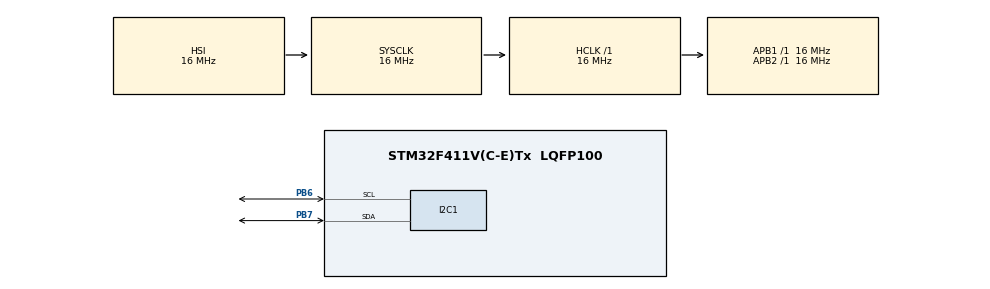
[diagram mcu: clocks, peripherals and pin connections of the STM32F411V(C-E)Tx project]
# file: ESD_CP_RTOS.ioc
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FREERTOS.Tasks01=defaultTask,-1,128,StartDefaultTask,Default,NULL,Dynamic,NULL,NULL;Task_IRSensor,1,128,Task_IR_Entry,Default,NULL,Dynamic,NULL,NULL;Regular_op,0,128,Regular_entry,Default,NULL,Dynamic,NULL,NULL
FREERTOS.configUSE_NEWLIB_REENTRANT=1
I2C1.I2C_Mode=I2C_Fast
Mcu.Family=STM32F4
Mcu.Name=STM32F411V(C-E)Tx
Mcu.Package=LQFP100
NVIC.PriorityGroup=NVIC_PRIORITYGROUP_4
NVIC.TIM1_UP_TIM10_IRQn=true\:15\:0\:false\:false\:true\:false\:false\:true
NVIC.TimeBase=TIM1_UP_TIM10_IRQn
NVIC.TimeBaseIP=TIM1
PA13.Mode=Serial_Wire
PA13.Signal=SYS_JTMS-SWDIO
PA14.Mode=Serial_Wire
PA14.Signal=SYS_JTCK-SWCLK
PB6.Mode=I2C
PB6.Signal=I2C1_SCL
PB7.Mode=I2C
PB7.Signal=I2C1_SDA
PH0\ -\ OSC_IN.Mode=HSE-External-Oscillator
PH0\ -\ OSC_IN.Signal=RCC_OSC_IN
PH1\ -\ OSC_OUT.Mode=HSE-External-Oscillator
PH1\ -\ OSC_OUT.Signal=RCC_OSC_OUT
ProjectManager.HeapSize=0x200
ProjectManager.StackSize=0x400
ProjectManager.TargetToolchain=STM32CubeIDE
RCC.AHBFreq_Value=16000000
RCC.APB1Freq_Value=16000000
RCC.APB2Freq_Value=16000000
RCC.CortexFreq_Value=16000000
RCC.HSE_VALUE=8000000
RCC.HSI_VALUE=16000000
RCC.LSE_VALUE=32768
RCC.SYSCLKFreq_VALUE=16000000
RCC.VCOOutputFreq_Value=192000000
VP_FREERTOS_VS_CMSIS_V1.Mode=CMSIS_V1
VP_SYS_VS_tim1.Mode=TIM1
board=custom

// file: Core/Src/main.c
/* USER CODE BEGIN Header */
/**
 ******************************************************************************
 * @file           : main.c
 * @brief          : Main program body
 ******************************************************************************
 * @attention
 *
 * <h2><center>&copy; Copyright (c) 2023 STMicroelectronics.
 * All rights reserved.</center></h2>
 *
 * This software component is licensed by ST under BSD 3-Clause license,
 * the "License"; You may not use this file except in compliance with the
 * License. You may obtain a copy of the License at:
 *                        opensource.org/licenses/BSD-3-Clause
 *
 ******************************************************************************
 */
/* USER CODE END Header */
#include "main.h"
#include "cmsis_os.h"

/* USER CODE BEGIN Includes */
#include "fonts.h"
#include "ssd1306.h"
#include "rtc.h"
#include "adc.h"
#include "ir_sensor.h"
#include "oled_ops.h"
#include "stdbool.h"
#include "timer.h"
/* USER CODE END Includes */

I2C_HandleTypeDef hi2c1;

osThreadId defaultTaskHandle;
osThreadId Sense_IRHandle;
osThreadId display_oledHandle;

void SystemClock_Config(void);
static void MX_GPIO_Init(void);
static void MX_I2C1_Init(void);
void StartDefaultTask(void const *argument);
void Sense_IR_Entry(void const *argument);
void display_oled_enter(void const *argument);

/* USER CODE BEGIN 0 */
#define PA5_SET 5
#define PA5_CLEAR 21
static bool clear_oled_left = true;
static bool clear_oled_right = true;
static bool clear_oled_both = true;
static bool clear_oled_default = true;
static unsigned char Left_Alert_NEW [] = {
0xFF, 0xFF, 0xFF, 0xFF, 0xFF, 0xFF, 0xFF, 0xFF, 0xFF, 0xFF, 0xFF, 0xFF, 0xFF, 0xFF, 0xFF, 0xFF,
0xFF, 0xFF, 0xFF, 0xFF, 0xFF, 0xFF, 0xFF, 0xFF, 0xFF, 0xFF, 0xFF, 0xFF, 0xFF, 0xFF, 0xFF, 0xFF,
0xFF, 0xFF, 0xFF, 0xFF, 0xFF, 0xFF, 0xFF, 0xFF, 0xFF, 0xFF, 0xFF, 0xFF, 0xFF, 0xFF, 0xFF, 0xFF,
0xFF, 0xFF, 0xFF, 0xFF, 0xFF, 0xFF, 0xFF, 0xF0, 0x03, 0xFF, 0xFF, 0xFF, 0xFF, 0xFF, 0xFF, 0xFF,
0xFF, 0xFF, 0xFF, 0xFF, 0xFF, 0xFF, 0xFF, 0xE0, 0x01, 0xFF, 0xFF, 0xFF, 0xFF, 0xFF, 0xFF, 0xFF,
0xFF, 0xFF, 0xFF, 0xFF, 0xFF, 0xFF, 0xFF, 0xE0, 0x01, 0xFF, 0xFF, 0xFF, 0xFF, 0xFF, 0xFF, 0xFF,
0xFF, 0xFF, 0xFF, 0xFF, 0xFF, 0xFF, 0xFF, 0xC0, 0x00, 0x7F, 0xFF, 0xFF, 0xFF, 0xFF, 0xFF, 0xFF,
0xFF, 0xFF, 0xFF, 0xFF, 0xFF, 0xFF, 0xFE, 0x00, 0x00, 0x1F, 0xFF, 0xFF, 0xFF, 0xFF, 0xFF, 0xFF,
0xFF, 0xFF, 0xFF, 0xFF, 0xFF, 0xFF, 0xFC, 0x00, 0x00, 0x0F, 0xFF, 0xFF, 0xFF, 0xFF, 0xFF, 0xFF,
0xFF, 0xFF, 0xFF, 0xFF, 0xFF, 0xFF, 0xFC, 0x00, 0x00, 0x0F, 0xFF, 0xFF, 0xFF, 0xFF, 0xFF, 0xFF,
0xFF, 0xFF, 0xFF, 0xFF, 0xFF, 0xFF, 0xFC, 0x00, 0x00, 0x0F, 0xFF, 0xFF, 0xFF, 0xFF, 0xFF, 0xFF,
0xFF, 0xFF, 0xFF, 0xFF, 0xFF, 0xFF, 0xF8, 0x00, 0x00, 0x0F, 0xFF, 0xFF, 0xFF, 0xFF, 0xFF, 0xFF,
0xFF, 0xFF, 0xFF, 0xFF, 0xFF, 0xFF, 0xF8, 0x00, 0x00, 0x0F, 0xFF, 0xFF, 0xFF, 0xFF, 0xFF, 0xFF,
0xFF, 0xFF, 0xFF, 0xFF, 0xFF, 0xFF, 0xF8, 0x00, 0x00, 0x0F, 0xFF, 0xFF, 0xFF, 0xFF, 0xFF, 0xFF,
0xFF, 0xFF, 0xFF, 0xFF, 0xFF, 0xFF, 0xF8, 0x00, 0x00, 0x0F, 0xFF, 0xFF, 0xFF, 0xFF, 0xFF, 0xFF,
0xFF, 0xFF, 0xFF, 0xFF, 0xFF, 0xFF, 0xF8, 0x00, 0x00, 0x0F, 0xFF, 0xFF, 0xFF, 0xFF, 0xFF, 0xFF,
0xFF, 0xFF, 0xFF, 0xFF, 0xFF, 0xFF, 0xFC, 0x03, 0xF8, 0x0F, 0xFF, 0xFF, 0xFF, 0xFF, 0xFF, 0xFF,
0xFF, 0xFF, 0xFF, 0xFF, 0xFF, 0xFF, 0xFC, 0x1F, 0xFE, 0x0F, 0xFF, 0xFF, 0xFF, 0xFF, 0xFF, 0xFF,
0xFF, 0xFF, 0xFF, 0xFF, 0xFF, 0xFF, 0xFC, 0x3F, 0xFF, 0x8F, 0xFF, 0xFF, 0xFF, 0xFF, 0xFF, 0xFF,
0xFF, 0xFF, 0xFF, 0xFF, 0xFF, 0xFF, 0xFC, 0x7F, 0xFF, 0x8F, 0xFF, 0xFF, 0xFF, 0xFF, 0xFF, 0xFF,
0xFF, 0xFF, 0xFF, 0xFF, 0xFF, 0xFF, 0xFC, 0x7F, 0xFF, 0xCF, 0xFF, 0xFF, 0xFF, 0xFF, 0xFF, 0xFF,
0xFF, 0xFF, 0xFF, 0xFF, 0xFF, 0xFF, 0xFC, 0x7F, 0xFF, 0xCF, 0xFF, 0xFF, 0xFF, 0xFF, 0xFF, 0xFF,
0xFF, 0xFF, 0xFF, 0xFF, 0xFF, 0xFF, 0xFC, 0x7F, 0xFF, 0x8F, 0xFF, 0xFF, 0xFF, 0xFF, 0xFF, 0xFF,
0xFF, 0xFF, 0xFF, 0xFF, 0xFF, 0xFF, 0xFC, 0x7F, 0xFF, 0x8F, 0xFF, 0xFF, 0xFF, 0xFF, 0xFF, 0xFF,
0xFF, 0xFF, 0xFF, 0xFF, 0xFF, 0xFF, 0xF0, 0x7F, 0xFF, 0x83, 0xFF, 0xFF, 0xFF, 0xFF, 0xFF, 0xFF,
0xFF, 0xFF, 0xFF, 0xFF, 0xFF, 0xFF, 0xF4, 0x3F, 0xFF, 0xAF, 0xFF, 0xFF, 0xFF, 0xFF, 0xFF, 0xFF,
0xFF, 0xFF, 0xFF, 0xFF, 0xFF, 0xFF, 0xFC, 0xBF, 0xFF, 0x2F, 0xFF, 0xFF, 0xFF, 0xFF, 0xFF, 0xFF,
0xFF, 0xFF, 0xFF, 0xFF, 0xFF, 0xFF, 0xFC, 0x80, 0x00, 0x2F, 0xFF, 0xFF, 0xFF, 0xFF, 0xFF, 0xFF,
0xFF, 0xFF, 0xFF, 0xFF, 0xFF, 0xFF, 0xFC, 0x80, 0x00, 0x6F, 0xFF, 0xFF, 0xFF, 0xFF, 0xFF, 0xFF,
0xFF, 0xFF, 0xFF, 0xFF, 0xFF, 0xFF, 0xFC, 0x80, 0x00, 0x6F, 0xFF, 0xFF, 0xFF, 0xFF, 0xFF, 0xFF,
0xFF, 0xFF, 0xFF, 0xFF, 0xFF, 0xFF, 0xFC, 0x80, 0x00, 0x6F, 0xFF, 0xFF, 0xFF, 0xFF, 0xFF, 0xFF,
0xFF, 0xFF, 0xFF, 0xFF, 0xFF, 0xFF, 0xFC, 0xC0, 0x00, 0x6F, 0xFF, 0xFF, 0xFF, 0xFF, 0xFF, 0xFF,
0xFF, 0xFF, 0xFF, 0xFF, 0xFF, 0xFF, 0xFC, 0xC0, 0x00, 0x6F, 0xFF, 0xFF, 0xFF, 0xFF, 0xFF, 0xFF,
0xFF, 0xFF, 0xFF, 0xFF, 0xFF, 0xFF, 0xFC, 0xC0, 0x00, 0x6F, 0xFF, 0xFF, 0xFF, 0xFF, 0xFF, 0xFF,
0xFF, 0xFF, 0xFF, 0xFF, 0xFF, 0xFF, 0xFC, 0xC0, 0x00, 0x6F, 0xFF, 0xFF, 0xFF, 0xFF, 0xFF, 0xFF,
0xFF, 0xFF, 0xFF, 0xFF, 0xFF, 0xFF, 0xFC, 0xC0, 0x00, 0x6F, 0xFF, 0xFF, 0xFF, 0xFF, 0xFF, 0xFF,
0xFF, 0xFF, 0xFF, 0xFF, 0xFF, 0xFF, 0xFC, 0xC0, 0x00, 0x6F, 0xFF, 0xFF, 0xFF, 0xFF, 0xFF, 0xFF,
0xFF, 0xFF, 0xFF, 0xFF, 0xFF, 0xFF, 0xFC, 0xC0, 0x00, 0x6F, 0xFF, 0xFF, 0xFF, 0xFF, 0xFF, 0xFF,
0xFF, 0xFF, 0xFF, 0xFF, 0xFF, 0xFF, 0xFC, 0xC0, 0x00, 0x6F, 0xFF, 0xFF, 0xFF, 0xFF, 0xFF, 0xFF,
0xFF, 0xFF, 0xFF, 0xFF, 0xFF, 0xFF, 0xFC, 0xC0, 0x00, 0x6F, 0xFF, 0xFF, 0xFF, 0xFF, 0xFF, 0xFF,
0xFF, 0xFF, 0xFF, 0xFF, 0xFF, 0xFF, 0xFC, 0xC0, 0x00, 0x4F, 0xFF, 0xFF, 0xFF, 0xFF, 0xFF, 0xFF,
0xFF, 0xFF, 0xFF, 0xFF, 0xFF, 0xFF, 0xFC, 0x40, 0x00, 0x4F, 0xFF, 0xFF, 0xFF, 0xFF, 0xFF, 0xFF,
0xFF, 0xFF, 0xFF, 0xFF, 0xFF, 0xFF, 0xF8, 0x00, 0x00, 0x0F, 0xFF, 0xFF, 0xFF, 0xFF, 0xFF, 0xFF,
0xFF, 0xFF, 0xFF, 0xFF, 0xFF, 0xFF, 0xF8, 0x00, 0x00, 0x0F, 0xFF, 0xFF, 0xFF, 0xFF, 0xFF, 0xFF,
0xFF, 0xFF, 0xFF, 0xFF, 0xFF, 0xFF, 0xF8, 0x1F, 0xFF, 0x0F, 0xFF, 0xFF, 0xFF, 0xFF, 0xFF, 0xFF,
0xFF, 0xFF, 0xFF, 0xFF, 0xFF, 0xDF, 0xF8, 0x3F, 0xFF, 0x0F, 0xFF, 0xFF, 0xFF, 0xFF, 0xFF, 0xFF,
0xFF, 0xFF, 0xFF, 0xFF, 0xFF, 0xDF, 0xFC, 0x1F, 0xFF, 0x0F, 0xFF, 0xFF, 0xFF, 0xFF, 0xFF, 0xFF,
0xFF, 0xFF, 0xFF, 0xFF, 0xFF, 0xCD, 0xFC, 0x1F, 0xFE, 0x0F, 0xFF, 0xFF, 0xFF, 0xFF, 0xFF, 0xFF,
0xFF, 0xFF, 0xFF, 0xFF, 0xFF, 0xED, 0xFC, 0x1F, 0xFE, 0x0F, 0xFF, 0xFF, 0xFF, 0xFF, 0xFF, 0xFF,
0xFF, 0xFF, 0xFF, 0xFF, 0xFF, 0xEC, 0x9C, 0x1F, 0xFE, 0x0F, 0xFF, 0xFF, 0xFF, 0xFF, 0xFF, 0xFF,
0xFF, 0xFF, 0xFF, 0xFF, 0xFF, 0xE6, 0xDC, 0x0F, 0xFC, 0x0F, 0xFF, 0xFF, 0xFF, 0xFF, 0xFF, 0xFF,
0xFF, 0xFF, 0xFF, 0xFF, 0xFF, 0xF6, 0x5C, 0x07, 0xF8, 0x1F, 0xFF, 0xFF, 0xFF, 0xFF, 0xFF, 0xFF,
0xFF, 0xFF, 0xFF, 0xFF, 0xFF, 0xF3, 0x4E, 0x00, 0x00, 0x1F, 0xFF, 0xFF, 0xFF, 0xFF, 0xFF, 0xFF,
0xFF, 0xFF, 0xFF, 0xFF, 0xFF, 0xFB, 0x2E, 0x00, 0x00, 0x1F, 0xFF, 0xFF, 0xFF, 0xFF, 0xFF, 0xFF,
0xFF, 0xFF, 0xFF, 0xFF, 0xFF, 0xF9, 0xA6, 0x00, 0x00, 0x3F, 0xFF, 0xFF, 0xFF, 0xFF, 0xFF, 0xFF,
0xFF, 0xFF, 0xFF, 0xFF, 0xFF, 0xFC, 0x93, 0xC0, 0x00, 0xFF, 0xFF, 0xFF, 0xFF, 0xFF, 0xFF, 0xFF,
0xFF, 0xFF, 0xFF, 0xFF, 0xFF, 0xFE, 0xC8, 0x7F, 0xFF, 0xFF, 0xFF, 0xFF, 0xFF, 0xFF, 0xFF, 0xFF,
0xFF, 0xFF, 0xFF, 0xFF, 0xFF, 0xFF, 0x66, 0x1F, 0xFF, 0xFF, 0xFF, 0xFF, 0xFF, 0xFF, 0xFF, 0xFF,
0xFF, 0xFF, 0xFF, 0xFF, 0xFF, 0xFF, 0x30, 0x07, 0xFF, 0xFF, 0xFF, 0xFF, 0xFF, 0xFF, 0xFF, 0xFF,
0xFF, 0xFF, 0xFF, 0xFF, 0xFF, 0xFF, 0x9E, 0x1F, 0xFF, 0xFF, 0xFF, 0xFF, 0xFF, 0xFF, 0xFF, 0xFF,
0xFF, 0xFF, 0xFF, 0xFF, 0xFF, 0xFF, 0xE3, 0xF8, 0xFF, 0xFF, 0xFF, 0xFF, 0xFF, 0xFF, 0xFF, 0xFF,
0xFF, 0xFF, 0xFF, 0xFF, 0xFF, 0xFF, 0xF0, 0x03, 0xFF, 0xFF, 0xFF, 0xFF, 0xFF, 0xFF, 0xFF, 0xFF,
0xFF, 0xFF, 0xFF, 0xFF, 0xFF, 0xFF, 0xFF, 0xFF, 0xFF, 0xFF, 0xFF, 0xFF, 0xFF, 0xFF, 0xFF, 0xFF,
0xFF, 0xFF, 0xFF, 0xFF, 0xFF, 0xFF, 0xFF, 0xFF, 0xFF, 0xFF, 0xFF, 0xFF, 0xFF, 0xFF, 0xFF, 0xFF
};

static unsigned char Both_Side_Alert_NEW [] = {
0xFF, 0xFF, 0xFF, 0xFF, 0xFF, 0xFF, 0xFF, 0xFF, 0xFF, 0xFF, 0xFF, 0xFF, 0xFF, 0xFF, 0xFF, 0xFF,
0xFF, 0xFF, 0xFF, 0xFF, 0xFF, 0xFF, 0xFF, 0xFF, 0xFF, 0xFF, 0xFF, 0xFF, 0xFF, 0xFF, 0xFF, 0xFF,
0xFF, 0xFF, 0xFF, 0xFF, 0xFF, 0xFF, 0xFF, 0xFF, 0xFF, 0xFF, 0xFF, 0xFF, 0xFF, 0xFF, 0xFF, 0xFF,
0xFF, 0xFF, 0xFF, 0xFF, 0xFF, 0xFF, 0xFF, 0xFF, 0xFF, 0xFF, 0xFF, 0xFF, 0xFF, 0xFF, 0xFF, 0xFF,
0xFF, 0xFF, 0xFF, 0xFF, 0xFF, 0xFF, 0xFF, 0xFF, 0xFF, 0xFF, 0xFF, 0xFF, 0xFF, 0xFF, 0xFF, 0xFF,
0xFF, 0xFF, 0xFF, 0xFF, 0xFF, 0xFF, 0xFF, 0xFF, 0xFF, 0xFF, 0xFF, 0xFF, 0xFF, 0xFF, 0xFF, 0xFF,
0xFF, 0xFF, 0xFF, 0xFF, 0xFF, 0xFF, 0xFF, 0xFF, 0xFF, 0xFF, 0xFF, 0xFF, 0xFF, 0xFF, 0xFF, 0xFF,
0xFF, 0xFF, 0xFF, 0xFF, 0xFF, 0xFF, 0xFF, 0xC0, 0x7F, 0xFF, 0xFF, 0xFF, 0xFF, 0xFF, 0xFF, 0xFF,
0xFF, 0xFF, 0xFF, 0xFF, 0xFF, 0xFF, 0xFF, 0x00, 0x1F, 0xFF, 0xFF, 0xFF, 0xFF, 0xFF, 0xFF, 0xFF,
0xFF, 0xFF, 0xFF, 0xFF, 0xFF, 0xFF, 0xFF, 0x00, 0x1F, 0xFF, 0xFF, 0xFF, 0xFF, 0xFF, 0xFF, 0xFF,
0xFF, 0xFF, 0xFF, 0xFF, 0xFF, 0xFF, 0xFE, 0x00, 0x0F, 0xFF, 0xFF, 0xFF, 0xFF, 0xFF, 0xFF, 0xFF,
0xFF, 0xFF, 0xFF, 0xFF, 0xFF, 0xFF, 0xF0, 0x00, 0x01, 0xFF, 0xFF, 0xFF, 0xFF, 0xFF, 0xFF, 0xFF,
0xFF, 0xFF, 0xFF, 0xFF, 0xFF, 0xFF, 0xF0, 0x00, 0x01, 0xFF, 0xFF, 0xFF, 0xFF, 0xFF, 0xFF, 0xFF,
0xFF, 0xFF, 0xFF, 0xFF, 0xFF, 0xFF, 0xE0, 0x00, 0x00, 0xFF, 0xFF, 0xFF, 0xFF, 0xFF, 0xFF, 0xFF,
0xFF, 0xFF, 0xFF, 0xFF, 0xFF, 0xFF, 0xE0, 0x00, 0x00, 0xFF, 0xFF, 0xFF, 0xFF, 0xFF, 0xFF, 0xFF,
0xFF, 0xFF, 0xFF, 0xFF, 0xFF, 0xFF, 0xE0, 0x00, 0x00, 0xFF, 0xFF, 0xFF, 0xFF, 0xFF, 0xFF, 0xFF,
0xFF, 0xFF, 0xFF, 0xFF, 0xFF, 0xFF, 0xE0, 0x00, 0x00, 0xFF, 0xFF, 0xFF, 0xFF, 0xFF, 0xFF, 0xFF,
0xFF, 0xFF, 0xFF, 0xFF, 0xFF, 0xFF, 0xE0, 0x00, 0x00, 0xFF, 0xFF, 0xFF, 0xFF, 0xFF, 0xFF, 0xFF,
0xFF, 0xFF, 0xFF, 0xFF, 0xFF, 0xFF, 0xE0, 0x00, 0x00, 0xFF, 0xFF, 0xFF, 0xFF, 0xFF, 0xFF, 0xFF,
0xFF, 0xFF, 0xFF, 0xFF, 0xFF, 0xFF, 0xE0, 0x00, 0x00, 0xFF, 0xFF, 0xFF, 0xFF, 0xFF, 0xFF, 0xFF,
0xFF, 0xFF, 0xFF, 0xFF, 0xFF, 0xFF, 0xE0, 0x7F, 0xC0, 0xFF, 0xFF, 0xFF, 0xFF, 0xFF, 0xFF, 0xFF,
0xFF, 0xFF, 0xFF, 0xFF, 0xFF, 0xFF, 0xE1, 0xFF, 0xF0, 0xFF, 0xFF, 0xFF, 0xFF, 0xFF, 0xFF, 0xFF,
0xFF, 0xFF, 0xFF, 0xFF, 0xFF, 0xFF, 0xE3, 0xFF, 0xF8, 0xFF, 0xFF, 0xFF, 0xFF, 0xFF, 0xFF, 0xFF,
0xFF, 0xFF, 0xFF, 0xFF, 0xFF, 0xFF, 0xE3, 0xFF, 0xFC, 0xFF, 0xFF, 0xFF, 0xFF, 0xFF, 0xFF, 0xFF,
0xFF, 0xFF, 0xFF, 0xFF, 0xFF, 0xFF, 0xE3, 0xFF, 0xFC, 0xFF, 0xFF, 0xFF, 0xFF, 0xFF, 0xFF, 0xFF,
0xFF, 0xFF, 0xFF, 0xFF, 0xFF, 0xFF, 0xE3, 0xFF, 0xF8, 0xFF, 0xFF, 0xFF, 0xFF, 0xFF, 0xFF, 0xFF,
0xFF, 0xFF, 0xFF, 0xFF, 0xFF, 0xFF, 0xE3, 0xFF, 0xF8, 0xFF, 0xFF, 0xFF, 0xFF, 0xFF, 0xFF, 0xFF,
0xFF, 0xFF, 0xFF, 0xFF, 0xFF, 0xFF, 0xC3, 0xFF, 0xF8, 0x7F, 0xFF, 0xFF, 0xFF, 0xFF, 0xFF, 0xFF,
0xFF, 0xFF, 0xFF, 0xFF, 0xFF, 0xFF, 0xE1, 0xFF, 0xF8, 0xFF, 0xFF, 0xFF, 0xFF, 0xFF, 0xFF, 0xFF,
0xFF, 0xFF, 0xFF, 0xFF, 0xFF, 0xFF, 0xE4, 0xFF, 0xF0, 0xFF, 0xFF, 0xFF, 0xFF, 0xFF, 0xFF, 0xFF,
0xFF, 0xFF, 0xFF, 0xFF, 0xFF, 0xFF, 0xE4, 0x00, 0x04, 0xFF, 0xFF, 0xFF, 0xFF, 0xFF, 0xFF, 0xFF,
0xFF, 0xFF, 0xFF, 0xFF, 0xFF, 0xFF, 0xE4, 0x00, 0x04, 0xFF, 0xFF, 0xFF, 0xFF, 0xFF, 0xFF, 0xFF,
0xFF, 0xFF, 0xFF, 0xFF, 0xFF, 0xFF, 0xE4, 0x00, 0x04, 0xFF, 0xFF, 0xFF, 0xFF, 0xFF, 0xFF, 0xFF,
0xFF, 0xFF, 0xFF, 0xFF, 0xFF, 0xFF, 0xE6, 0x00, 0x04, 0xFF, 0xFF, 0xFF, 0xFF, 0xFF, 0xFF, 0xFF,
0xFF, 0xFF, 0xFF, 0xFF, 0xFF, 0xFF, 0xE6, 0x00, 0x04, 0xFF, 0xFF, 0xFF, 0xFF, 0xFF, 0xFF, 0xFF,
0xFF, 0xFF, 0xFF, 0xFF, 0xFF, 0xFF, 0xE6, 0x00, 0x04, 0xFF, 0xFF, 0xFF, 0xFF, 0xFF, 0xFF, 0xFF,
0xFF, 0xFF, 0xFF, 0xFF, 0xFF, 0xFF, 0xE6, 0x00, 0x04, 0xFF, 0xFF, 0xFF, 0xFF, 0xFF, 0xFF, 0xFF,
0xFF, 0xFF, 0xFF, 0xFF, 0xFF, 0xFF, 0xE6, 0x00, 0x04, 0xFF, 0xFF, 0xFF, 0xFF, 0xFF, 0xFF, 0xFF,
0xFF, 0xFF, 0xFF, 0xFF, 0xFF, 0xFF, 0xE6, 0x00, 0x04, 0xFF, 0xFF, 0xFF, 0xFF, 0xFF, 0xFF, 0xFF,
0xFF, 0xFF, 0xFF, 0xFF, 0xFF, 0xFF, 0xE6, 0x00, 0x04, 0xFF, 0xFF, 0xFF, 0xFF, 0xFF, 0xFF, 0xFF,
0xFF, 0xFF, 0xFF, 0xFF, 0xFF, 0xFF, 0xE6, 0x00, 0x04, 0xFF, 0xFF, 0xFF, 0xFF, 0xFF, 0xFF, 0xFF,
0xFF, 0xFF, 0xFF, 0xFF, 0xFF, 0xFF, 0xE6, 0x00, 0x04, 0xFF, 0xFF, 0xFF, 0xFF, 0xFF, 0xFF, 0xFF,
0xFF, 0xFF, 0xFF, 0xFF, 0xFF, 0xFF, 0xE6, 0x00, 0x04, 0xFF, 0xFF, 0xFF, 0xFF, 0xFF, 0xFF, 0xFF,
0xFF, 0xFF, 0xFF, 0xFF, 0xFF, 0xFF, 0xE2, 0x00, 0x04, 0xFF, 0xFF, 0xFF, 0xFF, 0xFF, 0xFF, 0xFF,
0xFF, 0xFF, 0xFF, 0xFF, 0xFF, 0xFF, 0xE0, 0x00, 0x00, 0xFF, 0xFF, 0xFF, 0xFF, 0xFF, 0xFF, 0xFF,
0xFF, 0xFF, 0xFF, 0xFF, 0xFF, 0xFF, 0xE0, 0xFF, 0xE0, 0xFF, 0xFF, 0xFF, 0xFF, 0xFF, 0xFF, 0xFF,
0xFF, 0xFF, 0xFF, 0xFF, 0xFF, 0xFF, 0xE0, 0xFF, 0xF0, 0xFF, 0xFF, 0xFF, 0xFF, 0xFF, 0xFF, 0xFF,
0xFF, 0xFF, 0xFF, 0xFF, 0xFF, 0xFF, 0xE3, 0xFF, 0xF0, 0xFF, 0xFF, 0xFF, 0xFF, 0xFF, 0xFF, 0xFF,
0xFF, 0xFF, 0xFF, 0xFF, 0xFF, 0xFF, 0xE0, 0xFF, 0xF0, 0xFF, 0xFF, 0xFF, 0xFF, 0xFF, 0xFF, 0xFF,
0xFF, 0xFF, 0xFF, 0xFF, 0xFE, 0xFF, 0xE0, 0xFF, 0xE0, 0xFD, 0x7F, 0xFF, 0xFF, 0xFF, 0xFF, 0xFF,
0xFF, 0xFF, 0xFF, 0xFF, 0xFF, 0x77, 0xE0, 0xFF, 0xE0, 0xFD, 0x7F, 0xFF, 0xFF, 0xFF, 0xFF, 0xFF,
0xFF, 0xFF, 0xFF, 0xFF, 0xFF, 0x7B, 0xF0, 0x7F, 0xE1, 0xFD, 0xBF, 0xFF, 0xFF, 0xFF, 0xFF, 0xFF,
0xFF, 0xFF, 0xFF, 0xFF, 0xFF, 0xBB, 0x70, 0x3F, 0x81, 0xFE, 0xBF, 0xFF, 0xFF, 0xFF, 0xFF, 0xFF,
0xFF, 0xFF, 0xFF, 0xFF, 0xFF, 0x9D, 0x30, 0x00, 0x01, 0xDE, 0xBF, 0xFF, 0xFF, 0xFF, 0xFF, 0xFF,
0xFF, 0xFF, 0xFF, 0xFF, 0xFF, 0xDD, 0xB0, 0x00, 0x01, 0xDE, 0xBF, 0xFF, 0xFF, 0xFF, 0xFF, 0xFF,
0xFF, 0xFF, 0xFF, 0xFF, 0xFF, 0xEE, 0xD8, 0x00, 0x03, 0xDE, 0xBF, 0xFF, 0xFF, 0xFF, 0xFF, 0xFF,
0xFF, 0xFF, 0xFF, 0xFF, 0xFF, 0xE6, 0x6F, 0x00, 0x1F, 0xBD, 0xBF, 0xFF, 0xFF, 0xFF, 0xFF, 0xFF,
0xFF, 0xFF, 0xFF, 0xFF, 0xFF, 0xF7, 0x33, 0xFF, 0xFF, 0x3B, 0xBF, 0xFF, 0xFF, 0xFF, 0xFF, 0xFF,
0xFF, 0xFF, 0xFF, 0xFF, 0xFF, 0xF9, 0x98, 0x7F, 0xFC, 0x73, 0xBF, 0xFF, 0xFF, 0xFF, 0xFF, 0xFF,
0xFF, 0xFF, 0xFF, 0xFF, 0xFF, 0xFC, 0xE0, 0xFF, 0xC3, 0xE7, 0x7F, 0xFF, 0xFF, 0xFF, 0xFF, 0xFF,
0xFF, 0xFF, 0xFF, 0xFF, 0xFF, 0xFF, 0x7F, 0xFF, 0xFF, 0xDE, 0xFF, 0xFF, 0xFF, 0xFF, 0xFF, 0xFF,
0xFF, 0xFF, 0xFF, 0xFF, 0xFF, 0xFF, 0x9F, 0xFF, 0xFF, 0x39, 0xFF, 0xFF, 0xFF, 0xFF, 0xFF, 0xFF,
0xFF, 0xFF, 0xFF, 0xFF, 0xFF, 0xFF, 0xE3, 0x9F, 0xFC, 0xF3, 0xFF, 0xFF, 0xFF, 0xFF, 0xFF, 0xFF,
0xFF, 0xFF, 0xFF, 0xFF, 0xFF, 0xFF, 0xFC, 0x3F, 0xFF, 0xCF, 0xFF, 0xFF, 0xFF, 0xFF, 0xFF, 0xFF
};

static unsigned char Right_Alert_NEW [] = {
0xFF, 0xFF, 0xFF, 0xFF, 0xFF, 0xFF, 0xFF, 0xFF, 0xFF, 0xFF, 0xFF, 0xFF, 0xFF, 0xFF, 0xFF, 0xFF,
0xFF, 0xFF, 0xFF, 0xFF, 0xFF, 0xFF, 0xFF, 0xFF, 0xFF, 0xFF, 0xFF, 0xFF, 0xFF, 0xFF, 0xFF, 0xFF,
0xFF, 0xFF, 0xFF, 0xFF, 0xFF, 0xFF, 0xFF, 0xFF, 0xFF, 0xFF, 0xFF, 0xFF, 0xFF, 0xFF, 0xFF, 0xFF,
0xFF, 0xFF, 0xFF, 0xFF, 0xFF, 0xFF, 0xFF, 0x00, 0x1F, 0xFF, 0xFF, 0xFF, 0xFF, 0xFF, 0xFF, 0xFF,
0xFF, 0xFF, 0xFF, 0xFF, 0xFF, 0xFF, 0xFC, 0x00, 0x0F, 0xFF, 0xFF, 0xFF, 0xFF, 0xFF, 0xFF, 0xFF,
0xFF, 0xFF, 0xFF, 0xFF, 0xFF, 0xFF, 0xFB, 0x00, 0x0F, 0xFF, 0xFF, 0xFF, 0xFF, 0xFF, 0xFF, 0xFF,
0xFF, 0xFF, 0xFF, 0xFF, 0xFF, 0xFF, 0xF4, 0x00, 0x03, 0xFF, 0xFF, 0xFF, 0xFF, 0xFF, 0xFF, 0xFF,
0xFF, 0xFF, 0xFF, 0xFF, 0xFF, 0xFF, 0xE0, 0x00, 0x00, 0xFF, 0xFF, 0xFF, 0xFF, 0xFF, 0xFF, 0xFF,
0xFF, 0xFF, 0xFF, 0xFF, 0xFF, 0xFF, 0xE0, 0x00, 0x00, 0xFF, 0xFF, 0xFF, 0xFF, 0xFF, 0xFF, 0xFF,
0xFF, 0xFF, 0xFF, 0xFF, 0xFF, 0xFF, 0xE0, 0x00, 0x00, 0x7F, 0xFF, 0xFF, 0xFF, 0xFF, 0xFF, 0xFF,
0xFF, 0xFF, 0xFF, 0xFF, 0xFF, 0xFF, 0xC0, 0x00, 0x00, 0x7F, 0xFF, 0xFF, 0xFF, 0xFF, 0xFF, 0xFF,
0xFF, 0xFF, 0xFF, 0xFF, 0xFF, 0xFF, 0xC0, 0x00, 0x00, 0x7F, 0xFF, 0xFF, 0xFF, 0xFF, 0xFF, 0xFF,
0xFF, 0xFF, 0xFF, 0xFF, 0xFF, 0xFF, 0xC0, 0x00, 0x00, 0x7F, 0xFF, 0xFF, 0xFF, 0xFF, 0xFF, 0xFF,
0xFF, 0xFF, 0xFF, 0xFF, 0xFF, 0xFF, 0xC0, 0x00, 0x00, 0x7F, 0xFF, 0xFF, 0xFF, 0xFF, 0xFF, 0xFF,
0xFF, 0xFF, 0xFF, 0xFF, 0xFF, 0xFF, 0xC0, 0x00, 0x00, 0x7F, 0xFF, 0xFF, 0xFF, 0xFF, 0xFF, 0xFF,
0xFF, 0xFF, 0xFF, 0xFF, 0xFF, 0xFF, 0xC0, 0x00, 0x00, 0x7F, 0xFF, 0xFF, 0xFF, 0xFF, 0xFF, 0xFF,
0xFF, 0xFF, 0xFF, 0xFF, 0xFF, 0xFF, 0xC0, 0x3F, 0x80, 0x7F, 0xFF, 0xFF, 0xFF, 0xFF, 0xFF, 0xFF,
0xFF, 0xFF, 0xFF, 0xFF, 0xFF, 0xFF, 0xE0, 0xFF, 0xF0, 0x7F, 0xFF, 0xFF, 0xFF, 0xFF, 0xFF, 0xFF,
0xFF, 0xFF, 0xFF, 0xFF, 0xFF, 0xFF, 0xE3, 0xFF, 0xF8, 0x7F, 0xFF, 0xFF, 0xFF, 0xFF, 0xFF, 0xFF,
0xFF, 0xFF, 0xFF, 0xFF, 0xFF, 0xFF, 0xE3, 0xFF, 0xFC, 0x7F, 0xFF, 0xFF, 0xFF, 0xFF, 0xFF, 0xFF,
0xFF, 0xFF, 0xFF, 0xFF, 0xFF, 0xFF, 0xE3, 0xFF, 0xFC, 0x7F, 0xFF, 0xFF, 0xFF, 0xFF, 0xFF, 0xFF,
0xFF, 0xFF, 0xFF, 0xFF, 0xFF, 0xFF, 0xE3, 0xFF, 0xFC, 0x7F, 0xFF, 0xFF, 0xFF, 0xFF, 0xFF, 0xFF,
0xFF, 0xFF, 0xFF, 0xFF, 0xFF, 0xFF, 0xE3, 0xFF, 0xFC, 0x7F, 0xFF, 0xFF, 0xFF, 0xFF, 0xFF, 0xFF,
0xFF, 0xFF, 0xFF, 0xFF, 0xFF, 0xFF, 0xC3, 0xFF, 0xFC, 0x7F, 0xFF, 0xFF, 0xFF, 0xFF, 0xFF, 0xFF,
0xFF, 0xFF, 0xFF, 0xFF, 0xFF, 0xFF, 0x83, 0xFF, 0xFC, 0x1F, 0xFF, 0xFF, 0xFF, 0xFF, 0xFF, 0xFF,
0xFF, 0xFF, 0xFF, 0xFF, 0xFF, 0xFF, 0xE1, 0xFF, 0xF8, 0x7F, 0xFF, 0xFF, 0xFF, 0xFF, 0xFF, 0xFF,
0xFF, 0xFF, 0xFF, 0xFF, 0xFF, 0xFF, 0xE0, 0x00, 0x00, 0x7F, 0xFF, 0xFF, 0xFF, 0xFF, 0xFF, 0xFF,
0xFF, 0xFF, 0xFF, 0xFF, 0xFF, 0xFF, 0xE4, 0x00, 0x02, 0x7F, 0xFF, 0xFF, 0xFF, 0xFF, 0xFF, 0xFF,
0xFF, 0xFF, 0xFF, 0xFF, 0xFF, 0xFF, 0xE4, 0x00, 0x02, 0x7F, 0xFF, 0xFF, 0xFF, 0xFF, 0xFF, 0xFF,
0xFF, 0xFF, 0xFF, 0xFF, 0xFF, 0xFF, 0xE4, 0x00, 0x02, 0x7F, 0xFF, 0xFF, 0xFF, 0xFF, 0xFF, 0xFF,
0xFF, 0xFF, 0xFF, 0xFF, 0xFF, 0xFF, 0xE4, 0x00, 0x02, 0x7F, 0xFF, 0xFF, 0xFF, 0xFF, 0xFF, 0xFF,
0xFF, 0xFF, 0xFF, 0xFF, 0xFF, 0xFF, 0xE4, 0x00, 0x02, 0x7F, 0xFF, 0xFF, 0xFF, 0xFF, 0xFF, 0xFF,
0xFF, 0xFF, 0xFF, 0xFF, 0xFF, 0xFF, 0xE4, 0x00, 0x06, 0x7F, 0xFF, 0xFF, 0xFF, 0xFF, 0xFF, 0xFF,
0xFF, 0xFF, 0xFF, 0xFF, 0xFF, 0xFF, 0xE4, 0x00, 0x06, 0x7F, 0xFF, 0xFF, 0xFF, 0xFF, 0xFF, 0xFF,
0xFF, 0xFF, 0xFF, 0xFF, 0xFF, 0xFF, 0xE6, 0x00, 0x06, 0x7F, 0xFF, 0xFF, 0xFF, 0xFF, 0xFF, 0xFF,
0xFF, 0xFF, 0xFF, 0xFF, 0xFF, 0xFF, 0xE6, 0x00, 0x06, 0x7F, 0xFF, 0xFF, 0xFF, 0xFF, 0xFF, 0xFF,
0xFF, 0xFF, 0xFF, 0xFF, 0xFF, 0xFF, 0xE6, 0x00, 0x06, 0x7F, 0xFF, 0xFF, 0xFF, 0xFF, 0xFF, 0xFF,
0xFF, 0xFF, 0xFF, 0xFF, 0xFF, 0xFF, 0xC6, 0x00, 0x06, 0x7F, 0xFF, 0xFF, 0xFF, 0xFF, 0xFF, 0xFF,
0xFF, 0xFF, 0xFF, 0xFF, 0xFF, 0xFF, 0xC6, 0x00, 0x06, 0x7F, 0xFF, 0xFF, 0xFF, 0xFF, 0xFF, 0xFF,
0xFF, 0xFF, 0xFF, 0xFF, 0xFF, 0xFF, 0xC4, 0x00, 0x06, 0x7F, 0xFF, 0xFF, 0xFF, 0xFF, 0xFF, 0xFF,
0xFF, 0xFF, 0xFF, 0xFF, 0xFF, 0xFF, 0xC4, 0x00, 0x06, 0x7F, 0xFF, 0xFF, 0xFF, 0xFF, 0xFF, 0xFF,
0xFF, 0xFF, 0xFF, 0xFF, 0xFF, 0xFF, 0xC0, 0x00, 0x00, 0x7F, 0xFF, 0xFF, 0xFF, 0xFF, 0xFF, 0xFF,
0xFF, 0xFF, 0xFF, 0xFF, 0xFF, 0xFF, 0xC0, 0x00, 0x00, 0x7F, 0xFF, 0xFF, 0xFF, 0xFF, 0xFF, 0xFF,
0xFF, 0xFF, 0xFF, 0xFF, 0xFF, 0xFF, 0xC0, 0xFF, 0xF0, 0x7F, 0xFF, 0xFF, 0xFF, 0xFF, 0xFF, 0xFF,
0xFF, 0xFF, 0xFF, 0xFF, 0xFF, 0xFF, 0xC0, 0xFF, 0xF0, 0x7F, 0xFF, 0xFF, 0xFF, 0xFF, 0xFF, 0xFF,
0xFF, 0xFF, 0xFF, 0xFF, 0xFF, 0xFF, 0xC3, 0xFF, 0xF0, 0x7F, 0xFF, 0xFF, 0xFF, 0xFF, 0xFF, 0xFF,
0xFF, 0xFF, 0xFF, 0xFF, 0xFF, 0xFF, 0xC0, 0xFF, 0xF0, 0x7F, 0xFF, 0xFF, 0xFF, 0xFF, 0xFF, 0xFF,
0xFF, 0xFF, 0xFF, 0xFF, 0xFF, 0xFF, 0xC0, 0xFF, 0xF0, 0x7E, 0xFF, 0xFF, 0xFF, 0xFF, 0xFF, 0xFF,
0xFF, 0xFF, 0xFF, 0xFF, 0xFF, 0xFF, 0xE0, 0xFF, 0xF0, 0x7E, 0x4F, 0xFF, 0xFF, 0xFF, 0xFF, 0xFF,
0xFF, 0xFF, 0xFF, 0xFF, 0xFF, 0xFF, 0xE0, 0xFF, 0xE0, 0xF2, 0x6F, 0xFF, 0xFF, 0xFF, 0xFF, 0xFF,
0xFF, 0xFF, 0xFF, 0xFF, 0xFF, 0xFF, 0xE0, 0x7F, 0xC0, 0xF7, 0x6F, 0xFF, 0xFF, 0xFF, 0xFF, 0xFF,
0xFF, 0xFF, 0xFF, 0xFF, 0xFF, 0xFF, 0xE0, 0x0F, 0x00, 0xF7, 0x67, 0xFF, 0xFF, 0xFF, 0xFF, 0xFF,
0xFF, 0xFF, 0xFF, 0xFF, 0xFF, 0xFF, 0xF0, 0x00, 0x00, 0xF7, 0x67, 0xFF, 0xFF, 0xFF, 0xFF, 0xFF,
0xFF, 0xFF, 0xFF, 0xFF, 0xFF, 0xFF, 0xF0, 0x00, 0x01, 0xEF, 0x77, 0xFF, 0xFF, 0xFF, 0xFF, 0xFF,
0xFF, 0xFF, 0xFF, 0xFF, 0xFF, 0xFF, 0xF8, 0x00, 0x01, 0xEF, 0x77, 0xFF, 0xFF, 0xFF, 0xFF, 0xFF,
0xFF, 0xFF, 0xFF, 0xFF, 0xFF, 0xFF, 0xFF, 0xE0, 0x7F, 0x9E, 0x77, 0xFF, 0xFF, 0xFF, 0xFF, 0xFF,
0xFF, 0xFF, 0xFF, 0xFF, 0xFF, 0xFF, 0xFF, 0xFF, 0xF0, 0x3C, 0xF7, 0xFF, 0xFF, 0xFF, 0xFF, 0xFF,
0xFF, 0xFF, 0xFF, 0xFF, 0xFF, 0xFF, 0xFF, 0xFF, 0xE3, 0xF3, 0xCF, 0xFF, 0xFF, 0xFF, 0xFF, 0xFF,
0xFF, 0xFF, 0xFF, 0xFF, 0xFF, 0xFF, 0xFF, 0xFF, 0xFF, 0x87, 0x1F, 0xFF, 0xFF, 0xFF, 0xFF, 0xFF,
0xFF, 0xFF, 0xFF, 0xFF, 0xFF, 0xFF, 0xFF, 0xFF, 0xFC, 0x3C, 0x7F, 0xFF, 0xFF, 0xFF, 0xFF, 0xFF,
0xFF, 0xFF, 0xFF, 0xFF, 0xFF, 0xFF, 0xFF, 0xFF, 0xC1, 0xE1, 0xFF, 0xFF, 0xFF, 0xFF, 0xFF, 0xFF,
0xFF, 0xFF, 0xFF, 0xFF, 0xFF, 0xFF, 0xFF, 0xFF, 0xDF, 0x0F, 0xFF, 0xFF, 0xFF, 0xFF, 0xFF, 0xFF,
0xFF, 0xFF, 0xFF, 0xFF, 0xFF, 0xFF, 0xFF, 0xFF, 0xF0, 0x7F, 0xFF, 0xFF, 0xFF, 0xFF, 0xFF, 0xFF,
0xFF, 0xFF, 0xFF, 0xFF, 0xFF, 0xFF, 0xFF, 0xFF, 0xC7, 0xFF, 0xFF, 0xFF, 0xFF, 0xFF, 0xFF, 0xFF
};
/* USER CODE END 0 */

int main(void) {

	/* MCU Configuration--------------------------------------------------------*/

	/* Reset of all peripherals, Initializes the Flash interface and the Systick. */
	HAL_Init();

	/* Configure the system clock */
	SystemClock_Config();

	/* Initialize all configured peripherals */
	MX_GPIO_Init();
	MX_I2C1_Init();
	/* USER CODE BEGIN 2 */
	SSD1306_Init();
	ir_init();
	rtc_init();
	adc_init();
	BM_TIM2_Init();
	SSD1306_Clear();
	//Start_Timer();
	//HAL_Delay(1000);
	//get_timer_Count();
	/* USER CODE END 2 */

	/* Create the thread(s) */
	/* definition and creation of defaultTask */
	osThreadDef(defaultTask, StartDefaultTask, osPriorityBelowNormal, 0, 128);
	defaultTaskHandle = osThreadCreate(osThread(defaultTask), NULL);

	/* definition and creation of Sense_IR */
	osThreadDef(Sense_IR, Sense_IR_Entry, osPriorityAboveNormal, 0, 128);
	Sense_IRHandle = osThreadCreate(osThread(Sense_IR), NULL);

	/* definition and creation of display_oled */
	osThreadDef(display_oled, display_oled_enter, osPriorityNormal, 0, 128);
	display_oledHandle = osThreadCreate(osThread(display_oled), NULL);

	/* Start scheduler */
	osKernelStart();

	/* We should never get here as control is now taken by the scheduler */
	/* Infinite loop */
	while (1) {

	}
}

void SystemClock_Config(void) {
	RCC_OscInitTypeDef RCC_OscInitStruct = { 0 };
	RCC_ClkInitTypeDef RCC_ClkInitStruct = { 0 };

	/** Configure the main internal regulator output voltage
	 */
	__HAL_RCC_PWR_CLK_ENABLE();
	__HAL_PWR_VOLTAGESCALING_CONFIG(PWR_REGULATOR_VOLTAGE_SCALE1);
	/** Initializes the RCC Oscillators according to the specified parameters
	 * in the RCC_OscInitTypeDef structure.
	 */
	RCC_OscInitStruct.OscillatorType = RCC_OSCILLATORTYPE_HSI;
	RCC_OscInitStruct.HSIState = RCC_HSI_ON;
	RCC_OscInitStruct.HSICalibrationValue = RCC_HSICALIBRATION_DEFAULT;
	RCC_OscInitStruct.PLL.PLLState = RCC_PLL_NONE;
	if (HAL_RCC_OscConfig(&RCC_OscInitStruct) != HAL_OK) {
		Error_Handler();
	}
	/** Initializes the CPU, AHB and APB buses clocks
	 */
	RCC_ClkInitStruct.ClockType = RCC_CLOCKTYPE_HCLK | RCC_CLOCKTYPE_SYSCLK
			| RCC_CLOCKTYPE_PCLK1 | RCC_CLOCKTYPE_PCLK2;
	RCC_ClkInitStruct.SYSCLKSource = RCC_SYSCLKSOURCE_HSI;
	RCC_ClkInitStruct.AHBCLKDivider = RCC_SYSCLK_DIV1;
	RCC_ClkInitStruct.APB1CLKDivider = RCC_HCLK_DIV1;
	RCC_ClkInitStruct.APB2CLKDivider = RCC_HCLK_DIV1;

	if (HAL_RCC_ClockConfig(&RCC_ClkInitStruct, FLASH_LATENCY_0) != HAL_OK) {
		Error_Handler();
	}
}

static void MX_I2C1_Init(void) {

	hi2c1.Instance = I2C1;
	hi2c1.Init.ClockSpeed = 400000;
	hi2c1.Init.DutyCycle = I2C_DUTYCYCLE_2;
	hi2c1.Init.OwnAddress1 = 0;
	hi2c1.Init.AddressingMode = I2C_ADDRESSINGMODE_7BIT;
	hi2c1.Init.DualAddressMode = I2C_DUALADDRESS_DISABLE;
	hi2c1.Init.OwnAddress2 = 0;
	hi2c1.Init.GeneralCallMode = I2C_GENERALCALL_DISABLE;
	hi2c1.Init.NoStretchMode = I2C_NOSTRETCH_DISABLE;
	if (HAL_I2C_Init(&hi2c1) != HAL_OK) {
		Error_Handler();
	}

}

static void MX_GPIO_Init(void) {

	/* GPIO Ports Clock Enable */
	__HAL_RCC_GPIOH_CLK_ENABLE();
	__HAL_RCC_GPIOA_CLK_ENABLE();
	__HAL_RCC_GPIOB_CLK_ENABLE();

}

void StartDefaultTask(void const *argument) {
	/* USER CODE BEGIN 5 */
//  /* Infinite loop */
	while (1) {

	}
	/* USER CODE END 5 */
}

void Sense_IR_Entry(void const *argument) {
	/* USER CODE BEGIN Sense_IR_Entry */
	/* Infinite loop */
	for (;;) {
		check_ir_sensor();
		osDelay(100);
	}
	/* USER CODE END Sense_IR_Entry */
}

void display_oled_enter(void const *argument) {
	/* USER CODE BEGIN display_oled_enter */
	/* Infinite loop */
	for (;;) {
		if (return_left_status() && (!(return_right_status()))) {
			if (clear_oled_left) {
				SSD1306_Clear();
				clear_oled_left = false;
			}
			GPIOA->BSRR |= MASK(ENABLE_, PA5_SET); //Set the buzzer
			SSD1306_DrawBitmap(0, 0, Left_Alert_NEW, 128, 64, 1);
			SSD1306_UpdateScreen();
			get_timer_Count();						//GETTING THE TIMER COUNT
			clear_oled_right = true;
			clear_oled_both = true;
			clear_oled_default = true;
		} else if (return_right_status() && (!(return_left_status()))) {
			if (clear_oled_right) {
				SSD1306_Clear();
				clear_oled_right = false;
			}
			GPIOA->BSRR |= MASK(ENABLE_, PA5_SET); //Set the buzzer
			SSD1306_DrawBitmap(0, 0, Right_Alert_NEW, 128, 64, 1);
			SSD1306_UpdateScreen();
			get_timer_Count();
			clear_oled_left = true;
			clear_oled_default = true;
			clear_oled_both = true;
		} else if (return_both_status()) {
			if (clear_oled_both) {
				SSD1306_Clear();
				clear_oled_both = false;
			}
			GPIOA->BSRR |= MASK(ENABLE_, PA5_SET); //Set the buzzer
			SSD1306_DrawBitmap(0, 0, Both_Side_Alert_NEW, 128, 64, 1);
			SSD1306_UpdateScreen();
			get_timer_Count();
			clear_oled_left = true;
			clear_oled_right = true;
			clear_oled_default = true;
		} else {
			if (clear_oled_default) {
				SSD1306_Clear();
				clear_oled_default = false;
			}
			GPIOA->BSRR |= MASK(ENABLE_, PA5_CLEAR); //Clear the buzzer
			RTC_calculate_date();
			RTC_calculate_time();
			calculate_temperature();
			clear_oled_left = true;
			clear_oled_right = true;
			clear_oled_both = true;
			Time_Update();
		}
		osDelay(1);
	}
	/* USER CODE END display_oled_enter */
}

void HAL_TIM_PeriodElapsedCallback(TIM_HandleTypeDef *htim) {
	if (htim->Instance == TIM4) {
		HAL_IncTick();
	}
}

void Error_Handler(void) {
	__disable_irq();
	while (1) {
	}
}

/************************ (C) COPYRIGHT STMicroelectronics *****END OF FILE****/
